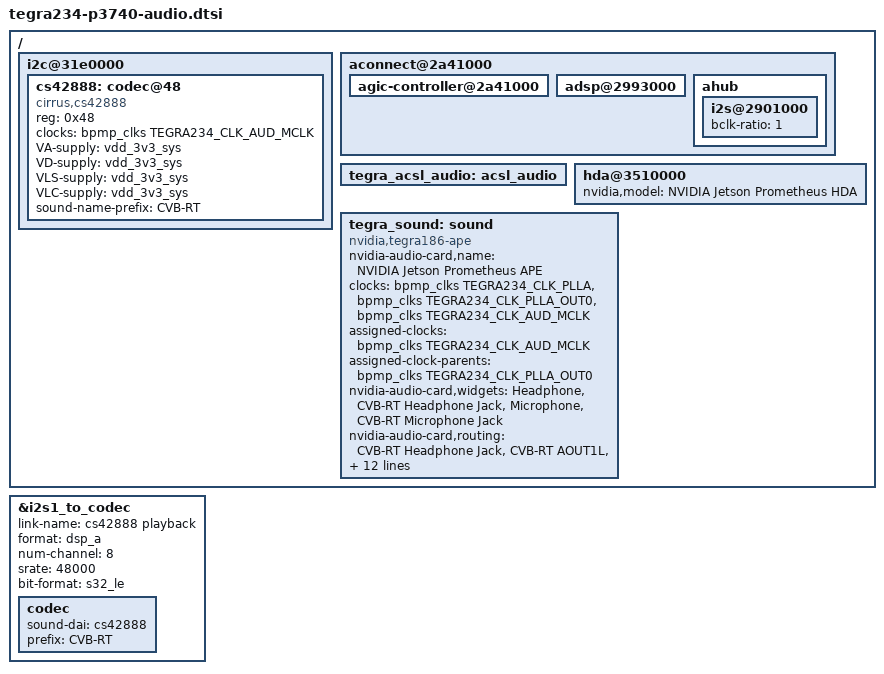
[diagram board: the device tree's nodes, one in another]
/*
 * T234 p3740 audio DTSI file.
 *
 * Copyright (c) 2021, NVIDIA CORPORATION.  All rights reserved.
 *
 * This program is free software; you can redistribute it and/or modify
 * it under the terms of the GNU General Public License as published by
 * the Free Software Foundation; version 2 of the License.
 *
 * This program is distributed in the hope that it will be useful, but WITHOUT
 * ANY WARRANTY; without even the implied warranty of MERCHANTABILITY or
 * FITNESS FOR A PARTICULAR PURPOSE.  See the GNU General Public License for
 * more details.
 */

#include <audio/tegra-platforms-audio-dai-links.dtsi>
#include <audio/tegra186-audio-dai-links.dtsi>
#include <dt-bindings/gpio/tegra234-gpio.h>
#include <dt-bindings/audio/tegra234-audio.h>

/ {
	i2c@31e0000 {
		cs42888: codec@48 {
			compatible = "cirrus,cs42888";
			reg = <0x48>;
			clocks = <&bpmp_clks TEGRA234_CLK_AUD_MCLK>;
			clock-names = "mclk";
			VA-supply = <&vdd_3v3_sys>;
			VD-supply = <&vdd_3v3_sys>;
			VLS-supply = <&vdd_3v3_sys>;
			VLC-supply = <&vdd_3v3_sys>;
			#sound-dai-cells = <0>;
			sound-name-prefix = "CVB-RT";
			status = "okay";
		};
	};

	aconnect@2a41000 {
		status = "okay";

		agic-controller@2a41000 {
			status = "okay";
		};

		adsp@2993000 {
			status = "okay";
		};

		ahub {
			status = "okay";

			/* I2S1 */
			i2s@2901000 {
				status = "okay";
				bclk-ratio = <1>;
			};
		};
	};

	tegra_acsl_audio: acsl_audio {
		status = "okay";
	};

	hda@3510000 {
		nvidia,model = "NVIDIA Jetson Prometheus HDA";
		status = "okay";
	};

	tegra_sound: sound {
		status = "okay";
		compatible = "nvidia,tegra186-ape";
		nvidia-audio-card,name = "NVIDIA Jetson Prometheus APE";
		clocks = <&bpmp_clks TEGRA234_CLK_PLLA>,
			 <&bpmp_clks TEGRA234_CLK_PLLA_OUT0>,
			 <&bpmp_clks TEGRA234_CLK_AUD_MCLK>;
		clock-names = "pll_a", "pll_a_out0", "extern1";
		assigned-clocks = <&bpmp_clks TEGRA234_CLK_AUD_MCLK>;
		assigned-clock-parents = <&bpmp_clks TEGRA234_CLK_PLLA_OUT0>;

		nvidia-audio-card,widgets =
			"Headphone",	"CVB-RT Headphone Jack",
			"Microphone",	"CVB-RT Microphone Jack";

		nvidia-audio-card,routing =
			"CVB-RT Headphone Jack",	"CVB-RT AOUT1L",
			"CVB-RT Headphone Jack",	"CVB-RT AOUT1R",
			"CVB-RT Headphone Jack",	"CVB-RT AOUT2L",
			"CVB-RT Headphone Jack",	"CVB-RT AOUT2R",
			"CVB-RT Headphone Jack",	"CVB-RT AOUT3L",
			"CVB-RT Headphone Jack",	"CVB-RT AOUT3R",
			"CVB-RT Headphone Jack",	"CVB-RT AOUT4L",
			"CVB-RT Headphone Jack",	"CVB-RT AOUT4R",
			"CVB-RT AIN1L",			"CVB-RT Microphone Jack", /* Front mic */
			"CVB-RT AIN1R",			"CVB-RT Microphone Jack", /* Rear mic */
			"CVB-RT AIN2L",			"CVB-RT Microphone Jack", /* Line-in L */
			"CVB-RT AIN2R",			"CVB-RT Microphone Jack"; /* Line-in R */

		nvidia-audio-card,mclk-fs = <512>;
	};
};

/*
 * Default config for all I2S dai links are
 * format = "i2s", bitclock-slave, frame-slave,
 * bitclock-noninversion, frame-noninversion,
 * Any change from default needs override on
 * platform specific files.
 */

&i2s1_to_codec {
	link-name = "cs42888 playback";

	/* Tegra will generate MCLK, SCLK, and FSYNC */
	format = "dsp_a"; /* TDM with 1-bit offset */
	num-channel = <8>;
	srate = <48000>;
	bit-format = "s32_le";

	codec {
		sound-dai = <&cs42888>;
		prefix = "CVB-RT";
	};
};
